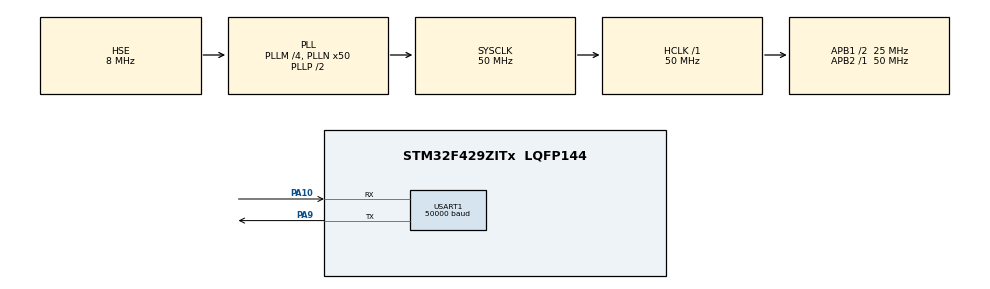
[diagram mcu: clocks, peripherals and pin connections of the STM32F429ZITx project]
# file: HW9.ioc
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Mcu.Family=STM32F4
Mcu.Name=STM32F429ZITx
Mcu.Package=LQFP144
NVIC.PriorityGroup=NVIC_PRIORITYGROUP_4
PA10.Mode=Asynchronous
PA10.Signal=USART1_RX
PA9.Mode=Asynchronous
PA9.Signal=USART1_TX
PH0/OSC_IN.Mode=HSE-External-Oscillator
PH0/OSC_IN.Signal=RCC_OSC_IN
PH1/OSC_OUT.Mode=HSE-External-Oscillator
PH1/OSC_OUT.Signal=RCC_OSC_OUT
ProjectManager.HeapSize=0x200
ProjectManager.StackSize=0x400
ProjectManager.TargetToolchain=EWARM V8.32
RCC.48MHZClocksFreq_Value=25000000
RCC.AHBFreq_Value=50000000
RCC.APB1CLKDivider=RCC_HCLK_DIV2
RCC.APB1Freq_Value=25000000
RCC.APB1TimFreq_Value=50000000
RCC.APB2Freq_Value=50000000
RCC.APB2TimFreq_Value=50000000
RCC.CortexFreq_Value=50000000
RCC.HCLKFreq_Value=50000000
RCC.HSE_VALUE=8000000
RCC.HSI_VALUE=16000000
RCC.LSE_VALUE=32768
RCC.PLLM=4
RCC.PLLN=50
RCC.PLLSourceVirtual=RCC_PLLSOURCE_HSE
RCC.SYSCLKFreq_VALUE=50000000
RCC.SYSCLKSource=RCC_SYSCLKSOURCE_PLLCLK
RCC.VCOOutputFreq_Value=100000000
USART1.BaudRate=50000
USART1.Parity=PARITY_EVEN
USART1.VirtualMode=VM_ASYNC
board=custom

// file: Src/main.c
/* USER CODE BEGIN Header */
/**
  ******************************************************************************
  * @file           : main.c
  * @brief          : Main program body
  ******************************************************************************
  * @attention
  *
  * <h2><center>&copy; Copyright (c) 2020 STMicroelectronics.
  * All rights reserved.</center></h2>
  *
  * This software component is licensed by ST under BSD 3-Clause license,
  * the "License"; You may not use this file except in compliance with the
  * License. You may obtain a copy of the License at:
  *                        opensource.org/licenses/BSD-3-Clause
  *
  ******************************************************************************
  */
/* USER CODE END Header */

#include "main.h"

UART_HandleTypeDef huart1;

/* USER CODE BEGIN PV */
uint8_t tmp1,tmp2,tmp3,tmp4,tmp5,tmp6  = 0;
uint8_t myTx1[6] = "ack\r\n";
uint8_t myTx2[7] = "nack\r\n";
uint8_t myRx1[1];
uint8_t myRx2[1];
uint8_t synErrorCount,charErrorCount = 0;

/* USER CODE END PV */

void SystemClock_Config(void);
static void MX_GPIO_Init(void);
static void MX_USART1_UART_Init(void);

int main(void)
{

  /* MCU Configuration--------------------------------------------------------*/

  /* Reset of all peripherals, Initializes the Flash interface and the Systick. */
  HAL_Init();

  /* Configure the system clock */
  SystemClock_Config();

  /* Initialize all configured peripherals */
  MX_GPIO_Init();
  MX_USART1_UART_Init();

  /* Infinite loop */
  /* USER CODE BEGIN WHILE */
  while (1)
  {
    tmp1 = __HAL_UART_GET_FLAG(&huart1, UART_FLAG_ORE);
    tmp2 = __HAL_UART_GET_IT_SOURCE(&huart1, UART_IT_ERR);
    tmp3 = __HAL_UART_GET_FLAG(&huart1, UART_FLAG_PE);
    tmp4 = __HAL_UART_GET_IT_SOURCE(&huart1, UART_IT_ERR);
    tmp5 = __HAL_UART_GET_FLAG(&huart1, UART_FLAG_FE);
    tmp6 = __HAL_UART_GET_IT_SOURCE(&huart1, UART_IT_ERR);
    /* UART Over-Run interrupt occurred ----------------------------------------*/
    if((tmp1 != RESET) && (tmp2 != RESET) && (tmp3 != RESET) && (tmp4 != RESET) && (tmp5 != RESET) && (tmp6 != RESET))
    {
      HAL_UART_Transmit_IT(&huart1,myTx1,6);                                     // trasmit "Ack" beacuse no errors
      HAL_UART_Receive_IT(&huart1,myRx1,1);                                     // reacive data and store it in myRx1[1]
      if (synErrorCount < 5 && myRx1[1] == 0x16){                               // "syn" is succefully received
           synErrorCount = 0;
           HAL_UART_Receive_IT(&huart1,myRx2,1);                             // reacive data and store it in myRx2[1]

      if (charErrorCount < 5 && myRx2[1] == 0x30){                          // "ascii "0" " is succefully received
          charErrorCount = 0;                                               // reset the CharErrorCount to 0
          HAL_UART_Transmit_IT(&huart1,myTx1,6);                                // trasmit "Ack" beacuse ascii "0" is recived
          while(1){                                                          // infinite while loop with return value 0 beaucse we have recived our char
            return 0;
          }
          }
      else {
        HAL_UART_Transmit_IT(&huart1,myTx2,7);                                   // trasmit "NAck" beacuse acsii "0" is not recived
        charErrorCount ++;                                                     // ascii "0" is not recived thu increment the eeror count
        if (charErrorCount>= 5){                                               // if error count is 5 or more then ener the while looop
          while(1){
            return 2;
          }
        }
      }
      }
      else {
        synErrorCount ++;                                                        // if "syn" is not recived then increment the error count
        if (synErrorCount>= 5){                                                 //if syn error is 5 or more enter the while loop with return 1
          while(1){
            return 1;
          }
        }
      }
    }
    else {
      HAL_UART_Transmit_IT(&huart1,myTx2,7);                                   // trasmit "NAck" beacuse an error in flag
    }

    /* USER CODE END WHILE */

  }
}

void SystemClock_Config(void)
{
  RCC_OscInitTypeDef RCC_OscInitStruct = {0};
  RCC_ClkInitTypeDef RCC_ClkInitStruct = {0};

  /** Configure the main internal regulator output voltage
  */
  __HAL_RCC_PWR_CLK_ENABLE();
  __HAL_PWR_VOLTAGESCALING_CONFIG(PWR_REGULATOR_VOLTAGE_SCALE3);
  /** Initializes the CPU, AHB and APB busses clocks
  */
  RCC_OscInitStruct.OscillatorType = RCC_OSCILLATORTYPE_HSE;
  RCC_OscInitStruct.HSEState = RCC_HSE_ON;
  RCC_OscInitStruct.PLL.PLLState = RCC_PLL_ON;
  RCC_OscInitStruct.PLL.PLLSource = RCC_PLLSOURCE_HSE;
  RCC_OscInitStruct.PLL.PLLM = 4;
  RCC_OscInitStruct.PLL.PLLN = 50;
  RCC_OscInitStruct.PLL.PLLP = RCC_PLLP_DIV2;
  RCC_OscInitStruct.PLL.PLLQ = 4;
  if (HAL_RCC_OscConfig(&RCC_OscInitStruct) != HAL_OK)
  {
    Error_Handler();
  }
  /** Initializes the CPU, AHB and APB busses clocks
  */
  RCC_ClkInitStruct.ClockType = RCC_CLOCKTYPE_HCLK|RCC_CLOCKTYPE_SYSCLK
                              |RCC_CLOCKTYPE_PCLK1|RCC_CLOCKTYPE_PCLK2;
  RCC_ClkInitStruct.SYSCLKSource = RCC_SYSCLKSOURCE_PLLCLK;
  RCC_ClkInitStruct.AHBCLKDivider = RCC_SYSCLK_DIV1;
  RCC_ClkInitStruct.APB1CLKDivider = RCC_HCLK_DIV2;
  RCC_ClkInitStruct.APB2CLKDivider = RCC_HCLK_DIV1;

  if (HAL_RCC_ClockConfig(&RCC_ClkInitStruct, FLASH_LATENCY_1) != HAL_OK)
  {
    Error_Handler();
  }
}

static void MX_USART1_UART_Init(void)
{

  huart1.Instance = USART1;
  huart1.Init.BaudRate = 50000;
  huart1.Init.WordLength = UART_WORDLENGTH_8B;
  huart1.Init.StopBits = UART_STOPBITS_1;
  huart1.Init.Parity = UART_PARITY_EVEN;
  huart1.Init.Mode = UART_MODE_TX_RX;
  huart1.Init.HwFlowCtl = UART_HWCONTROL_NONE;
  huart1.Init.OverSampling = UART_OVERSAMPLING_16;
  if (HAL_UART_Init(&huart1) != HAL_OK)
  {
    Error_Handler();
  }

}

static void MX_GPIO_Init(void)
{

  /* GPIO Ports Clock Enable */
  __HAL_RCC_GPIOH_CLK_ENABLE();
  __HAL_RCC_GPIOA_CLK_ENABLE();

}

void Error_Handler(void)
{
}

/************************ (C) COPYRIGHT STMicroelectronics *****END OF FILE****/
